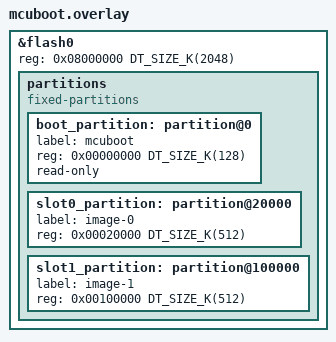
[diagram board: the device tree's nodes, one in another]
/* Extend flash0 to 2MB, remove ranges to fix DT_REG_ADDR double-add */
&flash0 {
    reg = <0x08000000 DT_SIZE_K(2048)>;
    /delete-property/ ranges;

    partitions {
        compatible = "fixed-partitions";
        #address-cells = <1>;
        #size-cells = <1>;
        ranges;

        boot_partition: partition@0 {
            label = "mcuboot";
            reg = <0x00000000 DT_SIZE_K(128)>;
            read-only;
        };

        slot0_partition: partition@20000 {
            label = "image-0";
            reg = <0x00020000 DT_SIZE_K(512)>;
        };

        slot1_partition: partition@100000 {
            label = "image-1";
            reg = <0x00100000 DT_SIZE_K(512)>;
        };
    };
};
